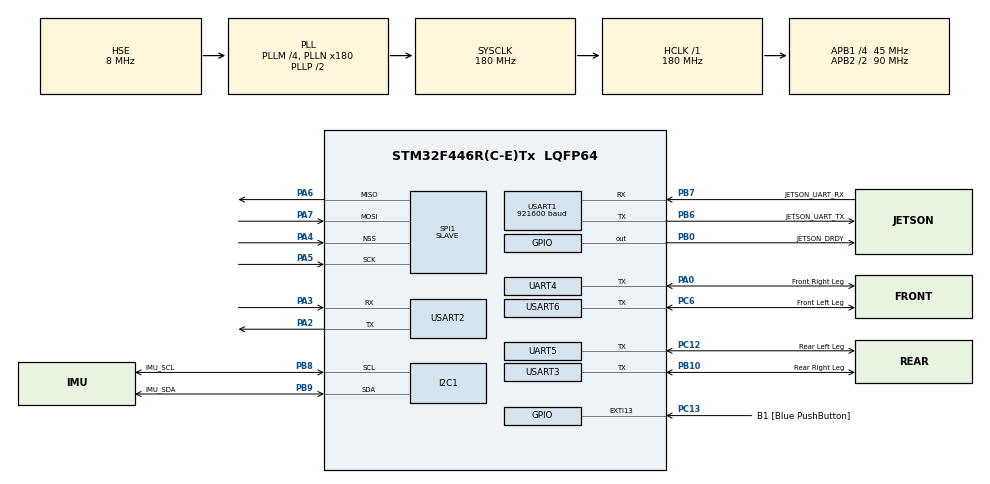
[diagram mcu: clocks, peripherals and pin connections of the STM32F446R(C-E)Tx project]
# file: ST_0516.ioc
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Dma.Request0=USART6_TX
Dma.Request1=USART6_RX
Dma.Request2=USART3_RX
Dma.Request3=USART3_TX
Dma.Request4=UART5_RX
Dma.Request5=UART5_TX
Dma.Request6=SPI1_RX
Dma.Request7=SPI1_TX
Dma.Request8=USART1_RX
Dma.Request9=USART1_TX
Dma.SPI1_RX.6.Direction=DMA_PERIPH_TO_MEMORY
Dma.SPI1_RX.6.FIFOMode=DMA_FIFOMODE_DISABLE
Dma.SPI1_RX.6.Instance=DMA2_Stream0
Dma.SPI1_RX.6.MemDataAlignment=DMA_MDATAALIGN_BYTE
Dma.SPI1_RX.6.MemInc=DMA_MINC_ENABLE
Dma.SPI1_RX.6.Mode=DMA_NORMAL
Dma.SPI1_RX.6.PeriphDataAlignment=DMA_PDATAALIGN_BYTE
Dma.SPI1_RX.6.PeriphInc=DMA_PINC_DISABLE
Dma.SPI1_RX.6.Priority=DMA_PRIORITY_LOW
Dma.SPI1_TX.7.Direction=DMA_MEMORY_TO_PERIPH
Dma.SPI1_TX.7.FIFOMode=DMA_FIFOMODE_DISABLE
Dma.SPI1_TX.7.Instance=DMA2_Stream3
Dma.SPI1_TX.7.MemDataAlignment=DMA_MDATAALIGN_BYTE
Dma.SPI1_TX.7.MemInc=DMA_MINC_ENABLE
Dma.SPI1_TX.7.Mode=DMA_NORMAL
Dma.SPI1_TX.7.PeriphDataAlignment=DMA_PDATAALIGN_BYTE
Dma.SPI1_TX.7.PeriphInc=DMA_PINC_DISABLE
Dma.SPI1_TX.7.Priority=DMA_PRIORITY_LOW
Dma.UART5_RX.4.Direction=DMA_PERIPH_TO_MEMORY
Dma.UART5_RX.4.FIFOMode=DMA_FIFOMODE_DISABLE
Dma.UART5_RX.4.Instance=DMA1_Stream0
Dma.UART5_RX.4.MemDataAlignment=DMA_MDATAALIGN_BYTE
Dma.UART5_RX.4.MemInc=DMA_MINC_ENABLE
Dma.UART5_RX.4.Mode=DMA_NORMAL
Dma.UART5_RX.4.PeriphDataAlignment=DMA_PDATAALIGN_BYTE
Dma.UART5_RX.4.PeriphInc=DMA_PINC_DISABLE
Dma.UART5_RX.4.Priority=DMA_PRIORITY_LOW
Dma.UART5_TX.5.Direction=DMA_MEMORY_TO_PERIPH
Dma.UART5_TX.5.FIFOMode=DMA_FIFOMODE_DISABLE
Dma.UART5_TX.5.Instance=DMA1_Stream7
Dma.UART5_TX.5.MemDataAlignment=DMA_MDATAALIGN_BYTE
Dma.UART5_TX.5.MemInc=DMA_MINC_ENABLE
Dma.UART5_TX.5.Mode=DMA_NORMAL
Dma.UART5_TX.5.PeriphDataAlignment=DMA_PDATAALIGN_BYTE
Dma.UART5_TX.5.PeriphInc=DMA_PINC_DISABLE
Dma.UART5_TX.5.Priority=DMA_PRIORITY_LOW
Dma.USART1_RX.8.Direction=DMA_PERIPH_TO_MEMORY
Dma.USART1_RX.8.FIFOMode=DMA_FIFOMODE_DISABLE
Dma.USART1_RX.8.Instance=DMA2_Stream2
Dma.USART1_RX.8.MemDataAlignment=DMA_MDATAALIGN_BYTE
Dma.USART1_RX.8.MemInc=DMA_MINC_ENABLE
Dma.USART1_RX.8.Mode=DMA_CIRCULAR
Dma.USART1_RX.8.PeriphDataAlignment=DMA_PDATAALIGN_BYTE
Dma.USART1_RX.8.PeriphInc=DMA_PINC_DISABLE
Dma.USART1_RX.8.Priority=DMA_PRIORITY_HIGH
Dma.USART1_TX.9.Direction=DMA_MEMORY_TO_PERIPH
Dma.USART1_TX.9.FIFOMode=DMA_FIFOMODE_DISABLE
Dma.USART1_TX.9.Instance=DMA2_Stream7
Dma.USART1_TX.9.MemDataAlignment=DMA_MDATAALIGN_BYTE
Dma.USART1_TX.9.MemInc=DMA_MINC_ENABLE
Dma.USART1_TX.9.Mode=DMA_NORMAL
Dma.USART1_TX.9.PeriphDataAlignment=DMA_PDATAALIGN_BYTE
Dma.USART1_TX.9.PeriphInc=DMA_PINC_DISABLE
Dma.USART1_TX.9.Priority=DMA_PRIORITY_HIGH
Dma.USART3_RX.2.Direction=DMA_PERIPH_TO_MEMORY
Dma.USART3_RX.2.FIFOMode=DMA_FIFOMODE_DISABLE
Dma.USART3_RX.2.Instance=DMA1_Stream1
Dma.USART3_RX.2.MemDataAlignment=DMA_MDATAALIGN_BYTE
Dma.USART3_RX.2.MemInc=DMA_MINC_ENABLE
Dma.USART3_RX.2.Mode=DMA_NORMAL
Dma.USART3_RX.2.PeriphDataAlignment=DMA_PDATAALIGN_BYTE
Dma.USART3_RX.2.PeriphInc=DMA_PINC_DISABLE
Dma.USART3_RX.2.Priority=DMA_PRIORITY_LOW
Dma.USART3_TX.3.Direction=DMA_MEMORY_TO_PERIPH
Dma.USART3_TX.3.FIFOMode=DMA_FIFOMODE_DISABLE
Dma.USART3_TX.3.Instance=DMA1_Stream3
Dma.USART3_TX.3.MemDataAlignment=DMA_MDATAALIGN_BYTE
Dma.USART3_TX.3.MemInc=DMA_MINC_ENABLE
Dma.USART3_TX.3.Mode=DMA_NORMAL
Dma.USART3_TX.3.PeriphDataAlignment=DMA_PDATAALIGN_BYTE
Dma.USART3_TX.3.PeriphInc=DMA_PINC_DISABLE
Dma.USART3_TX.3.Priority=DMA_PRIORITY_LOW
Dma.USART6_RX.1.Direction=DMA_PERIPH_TO_MEMORY
Dma.USART6_RX.1.FIFOMode=DMA_FIFOMODE_DISABLE
Dma.USART6_RX.1.Instance=DMA2_Stream1
Dma.USART6_RX.1.MemDataAlignment=DMA_MDATAALIGN_BYTE
Dma.USART6_RX.1.MemInc=DMA_MINC_ENABLE
Dma.USART6_RX.1.Mode=DMA_NORMAL
Dma.USART6_RX.1.PeriphDataAlignment=DMA_PDATAALIGN_BYTE
Dma.USART6_RX.1.PeriphInc=DMA_PINC_DISABLE
Dma.USART6_RX.1.Priority=DMA_PRIORITY_LOW
Dma.USART6_TX.0.Direction=DMA_MEMORY_TO_PERIPH
Dma.USART6_TX.0.FIFOMode=DMA_FIFOMODE_DISABLE
Dma.USART6_TX.0.Instance=DMA2_Stream6
Dma.USART6_TX.0.MemDataAlignment=DMA_MDATAALIGN_BYTE
Dma.USART6_TX.0.MemInc=DMA_MINC_ENABLE
Dma.USART6_TX.0.Mode=DMA_NORMAL
Dma.USART6_TX.0.PeriphDataAlignment=DMA_PDATAALIGN_BYTE
Dma.USART6_TX.0.PeriphInc=DMA_PINC_DISABLE
Dma.USART6_TX.0.Priority=DMA_PRIORITY_LOW
I2C1.I2C_Mode=I2C_Fast
Mcu.Family=STM32F4
Mcu.Name=STM32F446R(C-E)Tx
Mcu.Package=LQFP64
NVIC.DMA1_Stream0_IRQn=true\:0\:0\:false\:false\:true\:false\:true\:true
NVIC.DMA1_Stream1_IRQn=true\:0\:0\:false\:false\:true\:false\:true\:true
NVIC.DMA1_Stream3_IRQn=true\:0\:0\:false\:false\:true\:false\:true\:true
NVIC.DMA1_Stream7_IRQn=true\:0\:0\:false\:false\:true\:false\:true\:true
NVIC.DMA2_Stream0_IRQn=true\:0\:0\:false\:false\:true\:false\:true\:true
NVIC.DMA2_Stream1_IRQn=true\:0\:0\:false\:false\:true\:false\:true\:true
NVIC.DMA2_Stream2_IRQn=true\:0\:0\:true\:false\:true\:false\:true\:true
NVIC.DMA2_Stream3_IRQn=true\:0\:0\:false\:false\:true\:false\:true\:true
NVIC.DMA2_Stream6_IRQn=true\:0\:0\:false\:false\:true\:false\:true\:true
NVIC.DMA2_Stream7_IRQn=true\:0\:0\:true\:false\:true\:false\:true\:true
NVIC.PriorityGroup=NVIC_PRIORITYGROUP_0
NVIC.UART5_IRQn=true\:0\:0\:false\:false\:true\:true\:true\:true
NVIC.USART1_IRQn=true\:0\:0\:true\:false\:true\:true\:true\:true
NVIC.USART3_IRQn=true\:0\:0\:false\:false\:true\:true\:true\:true
NVIC.USART6_IRQn=true\:0\:0\:false\:false\:true\:true\:true\:true
PA0-WKUP.GPIO_Label=Front Right Leg
PA0-WKUP.GPIO_Speed=GPIO_SPEED_FREQ_HIGH
PA0-WKUP.Mode=Half_duplex(single_wire_mode)
PA0-WKUP.Signal=UART4_TX
PA13.GPIO_Label=TMS
PA13.Mode=Serial_Wire
PA13.Signal=SYS_JTMS-SWDIO
PA14.GPIO_Label=TCK
PA14.Mode=Serial_Wire
PA14.Signal=SYS_JTCK-SWCLK
PA2.Mode=Asynchronous
PA2.Signal=USART2_TX
PA3.Mode=Asynchronous
PA3.Signal=USART2_RX
PA4.Mode=NSS_Signal_Hard_Input
PA4.Signal=SPI1_NSS
PA5.Mode=Full_Duplex_Slave
PA5.Signal=SPI1_SCK
PA6.Mode=Full_Duplex_Slave
PA6.Signal=SPI1_MISO
PA7.Mode=Full_Duplex_Slave
PA7.Signal=SPI1_MOSI
PB0.GPIO_Label=JETSON_DRDY
PB0.Signal=GPIO_Output
PB10.GPIO_Label=Rear Right Leg
PB10.GPIO_Speed=GPIO_SPEED_FREQ_HIGH
PB10.Mode=Half_duplex(single_wire_mode)
PB10.Signal=USART3_TX
PB3.GPIO_Label=SWO
PB3.Signal=SYS_JTDO-SWO
PB6.GPIO_Label=JETSON_UART_TX
PB6.Mode=Asynchronous
PB6.Signal=USART1_TX
PB7.GPIO_Label=JETSON_UART_RX
PB7.Mode=Asynchronous
PB7.Signal=USART1_RX
PB8.GPIO_Label=IMU_SCL
PB8.GPIO_Pu=GPIO_PULLUP
PB8.Mode=I2C
PB8.Signal=I2C1_SCL
PB9.GPIO_Label=IMU_SDA
PB9.GPIO_Pu=GPIO_PULLUP
PB9.Mode=I2C
PB9.Signal=I2C1_SDA
PC12.GPIO_Label=Rear Left Leg
PC12.GPIO_Speed=GPIO_SPEED_FREQ_HIGH
PC12.Mode=Half_duplex(single_wire_mode)
PC12.Signal=UART5_TX
PC13.GPIO_Label=B1 [Blue PushButton]
PC13.GPIO_ModeDefaultEXTI=GPIO_MODE_IT_FALLING
PC13.Signal=GPXTI13
PC14-OSC32_IN.Signal=RCC_OSC32_IN
PC15-OSC32_OUT.Signal=RCC_OSC32_OUT
PC6.GPIO_Label=Front Left Leg
PC6.GPIO_Speed=GPIO_SPEED_FREQ_HIGH
PC6.Mode=Half_duplex(single_wire_mode)
PC6.Signal=USART6_TX
PH0-OSC_IN.Mode=HSE-External-Clock-Source
PH0-OSC_IN.Signal=RCC_OSC_IN
PH1-OSC_OUT.Mode=HSE-External-Clock-Source
PH1-OSC_OUT.Signal=RCC_OSC_OUT
ProjectManager.HeapSize=0x200
ProjectManager.StackSize=0x400
ProjectManager.TargetToolchain=STM32CubeIDE
RCC.48MHZClocksFreq_Value=84000000
RCC.AHBFreq_Value=180000000
RCC.APB1CLKDivider=RCC_HCLK_DIV4
RCC.APB1Freq_Value=45000000
RCC.APB1TimFreq_Value=90000000
RCC.APB2CLKDivider=RCC_HCLK_DIV2
RCC.APB2Freq_Value=90000000
RCC.APB2TimFreq_Value=180000000
RCC.CortexFreq_Value=180000000
RCC.FLatency-AdvancedSettings=FLASH_LATENCY_5
RCC.HCLKFreq_Value=180000000
RCC.HSE_VALUE=8000000
RCC.HSI_VALUE=16000000
RCC.PLLM=4
RCC.PLLN=180
RCC.PLLSourceVirtual=RCC_PLLSOURCE_HSE
RCC.SYSCLKFreq_VALUE=180000000
RCC.SYSCLKSource=RCC_SYSCLKSOURCE_PLLCLK
RCC.USBFreq_Value=180000000
RCC.VCOOutputFreq_Value=360000000
SPI1.Direction=SPI_DIRECTION_2LINES
SPI1.Mode=SPI_MODE_SLAVE
SPI1.VirtualNSS=VM_NSSHARD
SPI1.VirtualType=VM_SLAVE
UART4.BaudRate=1000000
UART4.VirtualMode=Asynchronous
UART5.BaudRate=1000000
UART5.VirtualMode=Asynchronous
USART1.BaudRate=921600
USART1.VirtualMode=VM_ASYNC
USART2.VirtualMode=VM_ASYNC
USART3.BaudRate=1000000
USART3.VirtualMode=VM_ASYNC
USART6.BaudRate=1000000
USART6.VirtualMode=VM_ASYNC
board=NUCLEO-F446RE

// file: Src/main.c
/* USER CODE BEGIN Header */
/**
  ******************************************************************************
  * @file           : main.c
  * @brief          : Main program body
  ******************************************************************************
  * @attention
  *
  * Copyright (c) 2026 STMicroelectronics.
  * All rights reserved.
  *
  * This software is licensed under terms that can be found in the LICENSE file
  * in the root directory of this software component.
  * If no LICENSE file comes with this software, it is provided AS-IS.
  *
  ******************************************************************************
  */
/* USER CODE END Header */
#include "main.h"
#include "dma.h"
#include "i2c.h"
#include "spi.h"
#include "usart.h"
#include "gpio.h"

/* USER CODE BEGIN Includes */
#include "control_loop.h"
#include "imu_bno055.h"
#include <stdio.h>

/* USER CODE END Includes */

void SystemClock_Config(void);

int main(void)
{

  /* MCU Configuration--------------------------------------------------------*/

  /* Reset of all peripherals, Initializes the Flash interface and the Systick. */
  HAL_Init();

  /* Configure the system clock */
  SystemClock_Config();

  /* Initialize all configured peripherals */
  MX_GPIO_Init();
  MX_DMA_Init();
  MX_USART3_UART_Init();
  MX_USART6_UART_Init();
  MX_I2C1_Init();
  MX_SPI1_Init();
  MX_UART5_Init();
  MX_USART2_UART_Init();
  MX_UART4_Init();
  MX_USART1_UART_Init();
  /* USER CODE BEGIN 2 */
  printf("\r\n[BOOT] BNO055 IMUPLUS init...\r\n");
  if (!bno055_init_imuplus(&hi2c1)) {
    printf("[BOOT] BNO055 init failed\r\n");
    Error_Handler();
  }
  printf("[BOOT] BNO055 init OK\r\n");

  control_loop_run();

  /* USER CODE END 2 */

  /* Infinite loop */
  while (1)
  {

  }
}

void SystemClock_Config(void)
{
  RCC_OscInitTypeDef RCC_OscInitStruct = {0};
  RCC_ClkInitTypeDef RCC_ClkInitStruct = {0};

  /** Configure the main internal regulator output voltage
  */
  __HAL_RCC_PWR_CLK_ENABLE();
  __HAL_PWR_VOLTAGESCALING_CONFIG(PWR_REGULATOR_VOLTAGE_SCALE1);

  /** Initializes the RCC Oscillators according to the specified parameters
  * in the RCC_OscInitTypeDef structure.
  */
  RCC_OscInitStruct.OscillatorType = RCC_OSCILLATORTYPE_HSE;
  RCC_OscInitStruct.HSEState = RCC_HSE_BYPASS;
  RCC_OscInitStruct.PLL.PLLState = RCC_PLL_ON;
  RCC_OscInitStruct.PLL.PLLSource = RCC_PLLSOURCE_HSE;
  RCC_OscInitStruct.PLL.PLLM = 4;
  RCC_OscInitStruct.PLL.PLLN = 180;
  RCC_OscInitStruct.PLL.PLLP = RCC_PLLP_DIV2;
  RCC_OscInitStruct.PLL.PLLQ = 2;
  RCC_OscInitStruct.PLL.PLLR = 2;
  if (HAL_RCC_OscConfig(&RCC_OscInitStruct) != HAL_OK)
  {
    Error_Handler();
  }

  /** Activate the Over-Drive mode
  */
  if (HAL_PWREx_EnableOverDrive() != HAL_OK)
  {
    Error_Handler();
  }

  /** Initializes the CPU, AHB and APB buses clocks
  */
  RCC_ClkInitStruct.ClockType = RCC_CLOCKTYPE_HCLK|RCC_CLOCKTYPE_SYSCLK
                              |RCC_CLOCKTYPE_PCLK1|RCC_CLOCKTYPE_PCLK2;
  RCC_ClkInitStruct.SYSCLKSource = RCC_SYSCLKSOURCE_PLLCLK;
  RCC_ClkInitStruct.AHBCLKDivider = RCC_SYSCLK_DIV1;
  RCC_ClkInitStruct.APB1CLKDivider = RCC_HCLK_DIV4;
  RCC_ClkInitStruct.APB2CLKDivider = RCC_HCLK_DIV2;

  if (HAL_RCC_ClockConfig(&RCC_ClkInitStruct, FLASH_LATENCY_5) != HAL_OK)
  {
    Error_Handler();
  }
}

void Error_Handler(void)
{
  __disable_irq();
  while (1)
  {
  }
}
